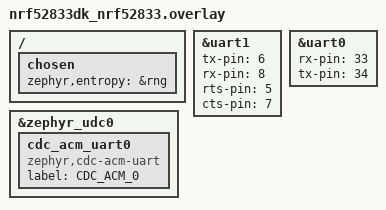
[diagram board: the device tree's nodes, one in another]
/*
 * Copyright (c) 2021 Nordic Semiconductor ASA
 *
 * SPDX-License-Identifier: LicenseRef-Nordic-5-Clause
 */

&uart1 {
	tx-pin = <6>;
	rx-pin = <8>;
	rts-pin = <5>;
	cts-pin = <7>;
};

&uart0 {
	rx-pin = <33>;
	tx-pin = <34>;
	/delete-property/ rts-pin;
	/delete-property/ cts-pin;
};

&zephyr_udc0 {
	cdc_acm_uart0: cdc_acm_uart0 {
		compatible = "zephyr,cdc-acm-uart";
		label = "CDC_ACM_0";
	};
};

/ {
	chosen {
		zephyr,entropy = &rng;
	};
};
